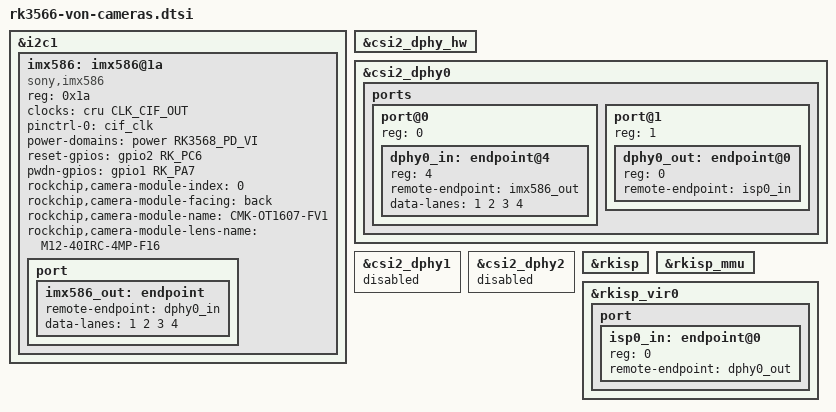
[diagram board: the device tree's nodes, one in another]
 // SPDX-License-Identifier: (GPL-2.0+ OR MIT)
/*
 * 
 *
 */

&i2c1 {
	status = "okay";


	imx586: imx586@1a {
		compatible = "sony,imx586";
		reg = <0x1a>;
		clocks = <&cru CLK_CIF_OUT>;
		clock-names = "xvclk";
		pinctrl-names = "default";
		pinctrl-0 = <&cif_clk>;

		power-domains = <&power RK3568_PD_VI>;

		reset-gpios = <&gpio2 RK_PC6 GPIO_ACTIVE_HIGH>;
		pwdn-gpios = <&gpio1 RK_PA7 GPIO_ACTIVE_HIGH>;
		
		rockchip,camera-module-index = <0>;
		rockchip,camera-module-facing = "back";
		rockchip,camera-module-name = "CMK-OT1607-FV1";
		rockchip,camera-module-lens-name = "M12-40IRC-4MP-F16";
		//lens-focus = <&cam_ircut0>;
		port {
			imx586_out: endpoint {
				remote-endpoint = <&dphy0_in>;
				data-lanes = <1 2 3 4>;
			};
		};
};

};

&csi2_dphy_hw {
	status = "okay";
};

&csi2_dphy0 {
	status = "okay";

	ports {
		#address-cells = <1>;
		#size-cells = <0>;
		port@0 {
			reg = <0>;
			#address-cells = <1>;
			#size-cells = <0>;

			dphy0_in: endpoint@4 {
				reg = <4>;
				remote-endpoint = <&imx586_out>;
				data-lanes = <1 2 3 4>;
			};
			
		};
		port@1 {
			reg = <1>;
			#address-cells = <1>;
			#size-cells = <0>;

			dphy0_out: endpoint@0 {
				reg = <0>;
				remote-endpoint = <&isp0_in>;
			};
		};
	};
};

&csi2_dphy1 {
	status = "disabled";
};

&csi2_dphy2 {
	status = "disabled";
};

&rkisp {
	status = "okay";
};

&rkisp_mmu {
	status = "okay";
};

&rkisp_vir0 {
	status = "okay";

	port {
		#address-cells = <1>;
		#size-cells = <0>;

		isp0_in: endpoint@0 {
			reg = <0>;
			remote-endpoint = <&dphy0_out>;
		};
	};
};
